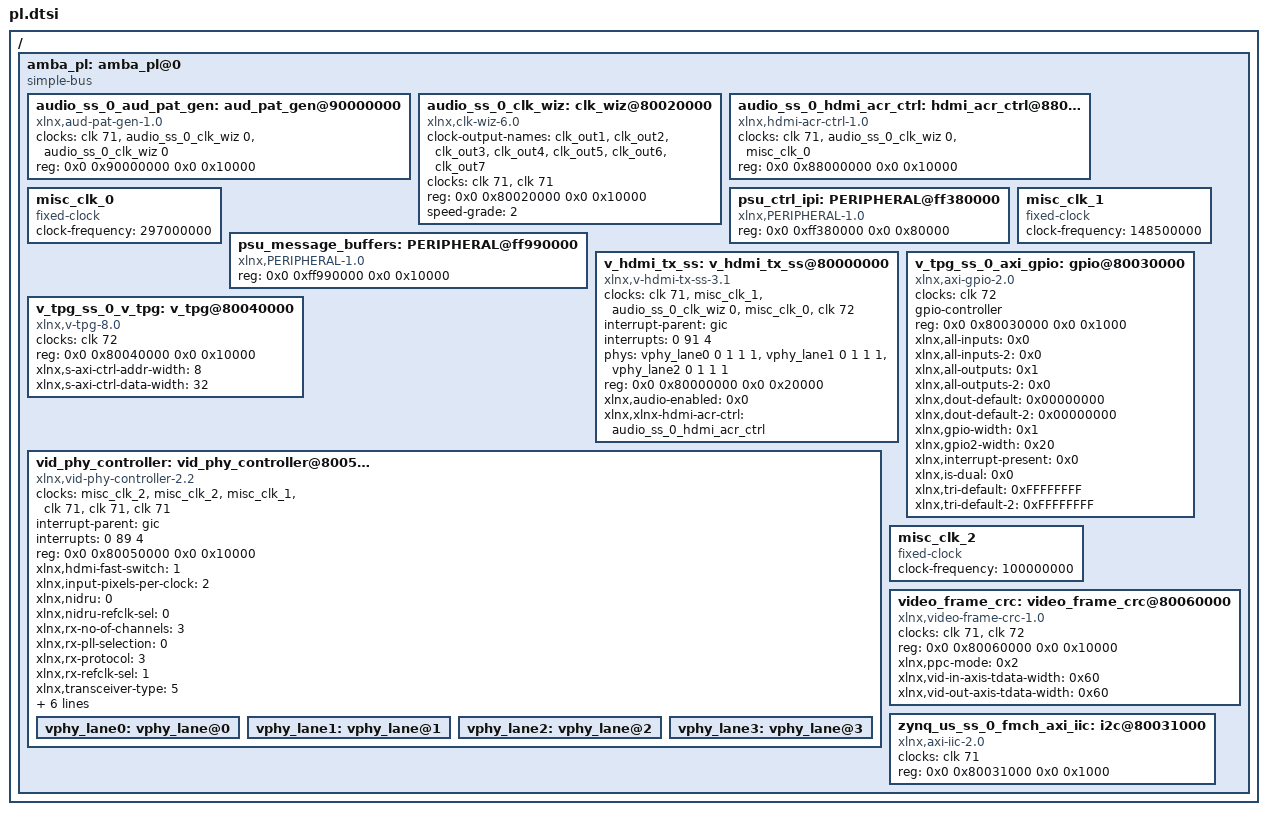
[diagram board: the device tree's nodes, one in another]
/*
 * CAUTION: This file is automatically generated by Xilinx.
 * Version: XSCT 2018.3.1
 * Today is: Wed Aug  7 17:33:02 2019
 */


/ {
	amba_pl: amba_pl@0 {
		#address-cells = <2>;
		#size-cells = <2>;
		compatible = "simple-bus";
		ranges ;
		audio_ss_0_aud_pat_gen: aud_pat_gen@90000000 {
			/* This is a place holder node for a custom IP, user may need to update the entries */
			clock-names = "axi_aclk", "aud_clk", "axis_clk";
			clocks = <&clk 71>, <&audio_ss_0_clk_wiz 0>, <&audio_ss_0_clk_wiz 0>;
			compatible = "xlnx,aud-pat-gen-1.0";
			reg = <0x0 0x90000000 0x0 0x10000>;
		};
		audio_ss_0_clk_wiz: clk_wiz@80020000 {
			#clock-cells = <1>;
			clock-names = "s_axi_aclk", "clk_in1";
			clock-output-names = "clk_out1", "clk_out2", "clk_out3", "clk_out4", "clk_out5", "clk_out6", "clk_out7";
			clocks = <&clk 71>, <&clk 71>;
			compatible = "xlnx,clk-wiz-6.0", "xlnx,clocking-wizard";
			reg = <0x0 0x80020000 0x0 0x10000>;
			speed-grade = <2>;
		};
		audio_ss_0_hdmi_acr_ctrl: hdmi_acr_ctrl@88000000 {
			clock-names = "axi_aclk", "aud_clk", "hdmi_clk";
			clocks = <&clk 71>, <&audio_ss_0_clk_wiz 0>, <&misc_clk_0>;
			compatible = "xlnx,hdmi-acr-ctrl-1.0", "xlnx,hdmi_act_ctrl";
			reg = <0x0 0x88000000 0x0 0x10000>;
		};
		misc_clk_0: misc_clk_0 {
			#clock-cells = <0>;
			clock-frequency = <297000000>;
			compatible = "fixed-clock";
		};
		psu_ctrl_ipi: PERIPHERAL@ff380000 {
			/* This is a place holder node for a custom IP, user may need to update the entries */
			compatible = "xlnx,PERIPHERAL-1.0";
			reg = <0x0 0xff380000 0x0 0x80000>;
		};
		psu_message_buffers: PERIPHERAL@ff990000 {
			/* This is a place holder node for a custom IP, user may need to update the entries */
			compatible = "xlnx,PERIPHERAL-1.0";
			reg = <0x0 0xff990000 0x0 0x10000>;
		};
		v_hdmi_tx_ss: v_hdmi_tx_ss@80000000 {
			/* User needs to change the property xlnx,audio-enabled=<0x1> based on the HDMI audio path */
			clock-names = "s_axi_cpu_aclk", "link_clk", "s_axis_audio_aclk", "video_clk", "s_axis_video_aclk";
			clocks = <&clk 71>, <&misc_clk_1>, <&audio_ss_0_clk_wiz 0>, <&misc_clk_0>, <&clk 72>;
			compatible = "xlnx,v-hdmi-tx-ss-3.1", "xlnx,v-hdmi-tx-ss-3.0";
			interrupt-names = "irq";
			interrupt-parent = <&gic>;
			interrupts = <0 91 4>;
			phy-names = "hdmi-phy0", "hdmi-phy1", "hdmi-phy2";
			phys = <&vphy_lane0 0 1 1 1>, <&vphy_lane1 0 1 1 1>, <&vphy_lane2 0 1 1 1>;
			reg = <0x0 0x80000000 0x0 0x20000>;
			xlnx,audio-enabled = <0x0>;
			xlnx,xlnx-hdmi-acr-ctrl = <&audio_ss_0_hdmi_acr_ctrl>;
		};
		misc_clk_1: misc_clk_1 {
			#clock-cells = <0>;
			clock-frequency = <148500000>;
			compatible = "fixed-clock";
		};
		v_tpg_ss_0_axi_gpio: gpio@80030000 {
			#gpio-cells = <3>;
			clock-names = "s_axi_aclk";
			clocks = <&clk 72>;
			compatible = "xlnx,axi-gpio-2.0", "xlnx,xps-gpio-1.00.a";
			gpio-controller ;
			reg = <0x0 0x80030000 0x0 0x1000>;
			xlnx,all-inputs = <0x0>;
			xlnx,all-inputs-2 = <0x0>;
			xlnx,all-outputs = <0x1>;
			xlnx,all-outputs-2 = <0x0>;
			xlnx,dout-default = <0x00000000>;
			xlnx,dout-default-2 = <0x00000000>;
			xlnx,gpio-width = <0x1>;
			xlnx,gpio2-width = <0x20>;
			xlnx,interrupt-present = <0x0>;
			xlnx,is-dual = <0x0>;
			xlnx,tri-default = <0xFFFFFFFF>;
			xlnx,tri-default-2 = <0xFFFFFFFF>;
		};
		v_tpg_ss_0_v_tpg: v_tpg@80040000 {
			clock-names = "ap_clk";
			clocks = <&clk 72>;
			compatible = "xlnx,v-tpg-8.0", "xlnx,v-tpg-5.0";
			reg = <0x0 0x80040000 0x0 0x10000>;
			xlnx,s-axi-ctrl-addr-width = <8>;
			xlnx,s-axi-ctrl-data-width = <32>;
		};
		vid_phy_controller: vid_phy_controller@80050000 {
			clock-names = "mgtrefclk0_pad_p_in", "mgtrefclk0_pad_n_in", "vid_phy_tx_axi4s_aclk", "vid_phy_sb_aclk", "vid_phy_axi4lite_aclk", "drpclk";
			clocks = <&misc_clk_2>, <&misc_clk_2>, <&misc_clk_1>, <&clk 71>, <&clk 71>, <&clk 71>;
			compatible = "xlnx,vid-phy-controller-2.2", "xlnx,vid-phy-controller-2.1";
			interrupt-names = "irq";
			interrupt-parent = <&gic>;
			interrupts = <0 89 4>;
			reg = <0x0 0x80050000 0x0 0x10000>;
			xlnx,hdmi-fast-switch = <1>;
			xlnx,input-pixels-per-clock = <2>;
			xlnx,nidru = <0>;
			xlnx,nidru-refclk-sel = <0>;
			xlnx,rx-no-of-channels = <3>;
			xlnx,rx-pll-selection = <0>;
			xlnx,rx-protocol = <3>;
			xlnx,rx-refclk-sel = <1>;
			xlnx,transceiver-type = <5>;
			xlnx,transceiver-width = <2>;
			xlnx,tx-buffer-bypass = <1>;
			xlnx,tx-no-of-channels = <3>;
			xlnx,tx-pll-selection = <6>;
			xlnx,tx-protocol = <1>;
			xlnx,tx-refclk-sel = <0>;
			vphy_lane0: vphy_lane@0 {
				#phy-cells = <4>;
			};
			vphy_lane1: vphy_lane@1 {
				#phy-cells = <4>;
			};
			vphy_lane2: vphy_lane@2 {
				#phy-cells = <4>;
			};
			vphy_lane3: vphy_lane@3 {
				#phy-cells = <4>;
			};
		};
		misc_clk_2: misc_clk_2 {
			#clock-cells = <0>;
			clock-frequency = <100000000>;
			compatible = "fixed-clock";
		};
		video_frame_crc: video_frame_crc@80060000 {
			/* This is a place holder node for a custom IP, user may need to update the entries */
			clock-names = "s_axi_aclk", "vid_in_axis_aclk";
			clocks = <&clk 71>, <&clk 72>;
			compatible = "xlnx,video-frame-crc-1.0";
			reg = <0x0 0x80060000 0x0 0x10000>;
			xlnx,ppc-mode = <0x2>;
			xlnx,vid-in-axis-tdata-width = <0x60>;
			xlnx,vid-out-axis-tdata-width = <0x60>;
		};
		zynq_us_ss_0_fmch_axi_iic: i2c@80031000 {
			#address-cells = <1>;
			#size-cells = <0>;
			clock-names = "s_axi_aclk";
			clocks = <&clk 71>;
			compatible = "xlnx,axi-iic-2.0", "xlnx,xps-iic-2.00.a";
			reg = <0x0 0x80031000 0x0 0x1000>;
		};
	};
};
